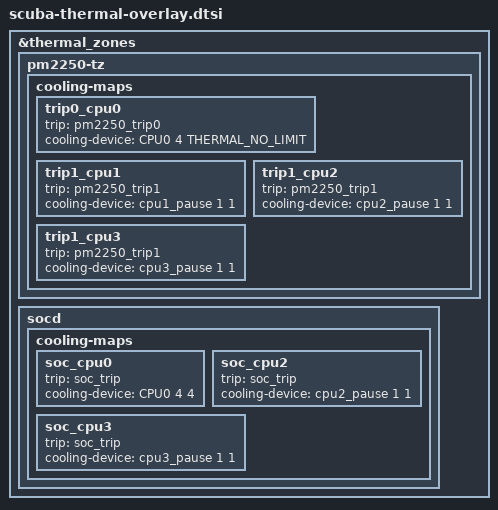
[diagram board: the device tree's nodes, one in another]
#include <dt-bindings/thermal/thermal.h>

&thermal_zones {
	pm2250-tz {
		cooling-maps {
			trip0_cpu0 {
				trip = <&pm2250_trip0>;
				cooling-device =
					<&CPU0 4 THERMAL_NO_LIMIT>;
			};

			trip1_cpu1 {
				trip = <&pm2250_trip1>;
				cooling-device = <&cpu1_pause 1 1>;
			};

			trip1_cpu2 {
				trip = <&pm2250_trip1>;
				cooling-device = <&cpu2_pause 1 1>;
			};

			trip1_cpu3 {
				trip = <&pm2250_trip1>;
				cooling-device = <&cpu3_pause 1 1>;
			};
		};
	};

	socd {
		cooling-maps {
			soc_cpu0 {
				trip = <&soc_trip>;
				cooling-device =
					<&CPU0 4 4>;
			};

			soc_cpu2 {
				trip = <&soc_trip>;
				cooling-device = <&cpu2_pause 1 1>;
			};

			soc_cpu3 {
				trip = <&soc_trip>;
				cooling-device = <&cpu3_pause 1 1>;
			};
		};
	};
};
